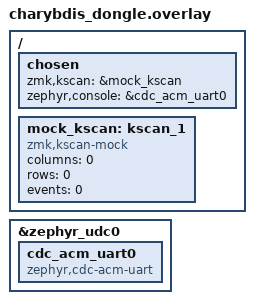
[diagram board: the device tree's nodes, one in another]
#include "charybdis.dtsi"

/ {
    chosen {
        zmk,kscan = &mock_kscan;
        zephyr,console = &cdc_acm_uart0;
    };

    mock_kscan: kscan_1 {
        compatible = "zmk,kscan-mock";
        columns = <0>;
        rows = <0>;
        events = <0>;
    };
};

&zephyr_udc0 {
    cdc_acm_uart0: cdc_acm_uart0 {
        compatible = "zephyr,cdc-acm-uart";
    };
};
